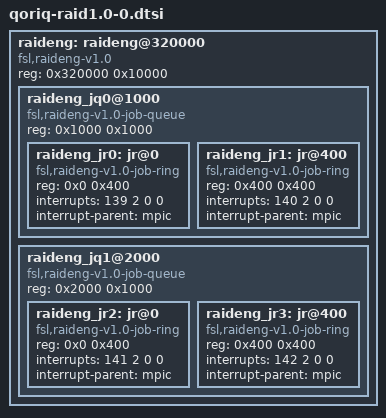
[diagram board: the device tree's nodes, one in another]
raideng: raideng@320000 {
	compatible = "fsl,raideng-v1.0";
	#address-cells = <1>;
	#size-cells = <1>;
	reg = <0x320000 0x10000>;
	ranges = <0 0x320000 0x10000>;
	raideng_jq0@1000 {
		compatible = "fsl,raideng-v1.0-job-queue";
		#address-cells = <1>;
		#size-cells = <1>;
		reg = <0x1000 0x1000>;
		ranges = <0x0 0x1000 0x1000>;
		raideng_jr0: jr@0 {
			compatible = "fsl,raideng-v1.0-job-ring", "fsl,raideng-v1.0-hp-ring";
			reg = <0x0 0x400>;
			interrupts = <139 2 0 0>;
			interrupt-parent = <&mpic>;
		};
		raideng_jr1: jr@400 {
			compatible = "fsl,raideng-v1.0-job-ring", "fsl,raideng-v1.0-lp-ring";
			reg = <0x400 0x400>;
			interrupts = <140 2 0 0>;
			interrupt-parent = <&mpic>;
		};
	};
	raideng_jq1@2000 {
		compatible = "fsl,raideng-v1.0-job-queue";
		#address-cells = <1>;
		#size-cells = <1>;
		reg = <0x2000 0x1000>;
		ranges = <0x0 0x2000 0x1000>;
		raideng_jr2: jr@0 {
			compatible = "fsl,raideng-v1.0-job-ring", "fsl,raideng-v1.0-hp-ring";
			reg = <0x0 0x400>;
			interrupts = <141 2 0 0>;
			interrupt-parent = <&mpic>;
		};
		raideng_jr3: jr@400 {
			compatible = "fsl,raideng-v1.0-job-ring", "fsl,raideng-v1.0-lp-ring";
			reg = <0x400 0x400>;
			interrupts = <142 2 0 0>;
			interrupt-parent = <&mpic>;
		};
	};
};
